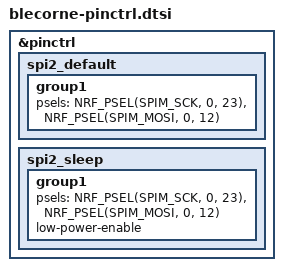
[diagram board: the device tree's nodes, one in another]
/*
 * Copyright (c) 2026 jack@pngu.org
 * SPDX-License-Identifier: MIT
*/

&pinctrl {
    spi2_default: spi2_default {
        group1 {
            psels = <NRF_PSEL(SPIM_SCK, 0, 23)>,
                    <NRF_PSEL(SPIM_MOSI, 0, 12)>;
        };
    };

    spi2_sleep: spi2_sleep {
        group1 {
            psels = <NRF_PSEL(SPIM_SCK, 0, 23)>,
                    <NRF_PSEL(SPIM_MOSI, 0, 12)>;
            low-power-enable;
        };
    };
};
